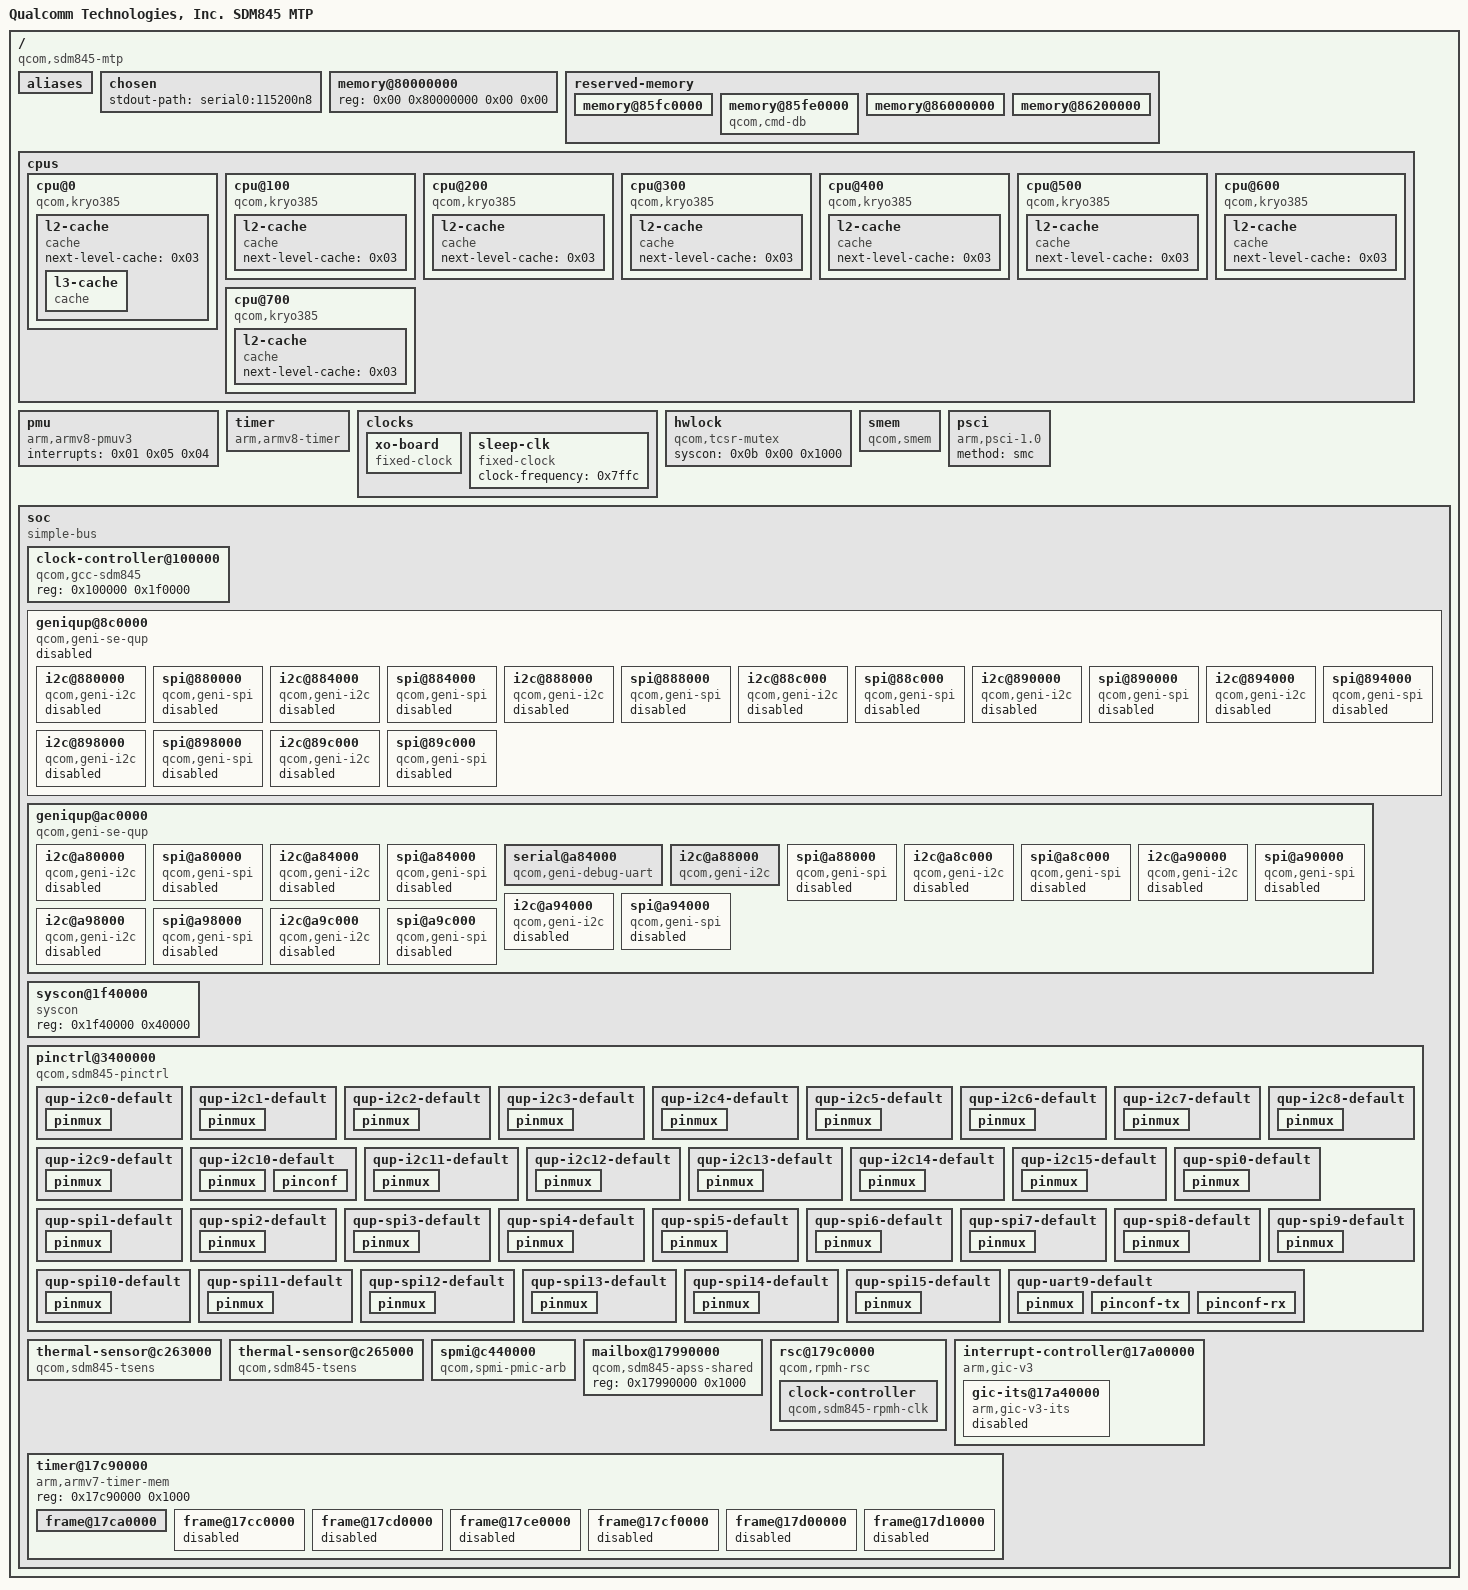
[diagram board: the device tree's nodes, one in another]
/dts-v1/;

/ {
	interrupt-parent = <0x01>;
	#address-cells = <0x02>;
	#size-cells = <0x02>;
	model = "Qualcomm Technologies, Inc. SDM845 MTP";
	compatible = "qcom,sdm845-mtp";

	aliases {
		i2c0 = "/soc/geniqup@8c0000/i2c@880000";
		i2c1 = "/soc/geniqup@8c0000/i2c@884000";
		i2c2 = "/soc/geniqup@8c0000/i2c@888000";
		i2c3 = "/soc/geniqup@8c0000/i2c@88c000";
		i2c4 = "/soc/geniqup@8c0000/i2c@890000";
		i2c5 = "/soc/geniqup@8c0000/i2c@894000";
		i2c6 = "/soc/geniqup@8c0000/i2c@898000";
		i2c7 = "/soc/geniqup@8c0000/i2c@89c000";
		i2c8 = "/soc/geniqup@ac0000/i2c@a80000";
		i2c9 = "/soc/geniqup@ac0000/i2c@a84000";
		i2c10 = "/soc/geniqup@ac0000/i2c@a88000";
		i2c11 = "/soc/geniqup@ac0000/i2c@a8c000";
		i2c12 = "/soc/geniqup@ac0000/i2c@a90000";
		i2c13 = "/soc/geniqup@ac0000/i2c@a94000";
		i2c14 = "/soc/geniqup@ac0000/i2c@a98000";
		i2c15 = "/soc/geniqup@ac0000/i2c@a9c000";
		spi0 = "/soc/geniqup@8c0000/spi@880000";
		spi1 = "/soc/geniqup@8c0000/spi@884000";
		spi2 = "/soc/geniqup@8c0000/spi@888000";
		spi3 = "/soc/geniqup@8c0000/spi@88c000";
		spi4 = "/soc/geniqup@8c0000/spi@890000";
		spi5 = "/soc/geniqup@8c0000/spi@894000";
		spi6 = "/soc/geniqup@8c0000/spi@898000";
		spi7 = "/soc/geniqup@8c0000/spi@89c000";
		spi8 = "/soc/geniqup@ac0000/spi@a80000";
		spi9 = "/soc/geniqup@ac0000/spi@a84000";
		spi10 = "/soc/geniqup@ac0000/spi@a88000";
		spi11 = "/soc/geniqup@ac0000/spi@a8c000";
		spi12 = "/soc/geniqup@ac0000/spi@a90000";
		spi13 = "/soc/geniqup@ac0000/spi@a94000";
		spi14 = "/soc/geniqup@ac0000/spi@a98000";
		spi15 = "/soc/geniqup@ac0000/spi@a9c000";
		serial0 = "/soc/geniqup@ac0000/serial@a84000";
	};

	chosen {
		stdout-path = "serial0:115200n8";
	};

	memory@80000000 {
		device_type = "memory";
		reg = <0x00 0x80000000 0x00 0x00>;
	};

	reserved-memory {
		#address-cells = <0x02>;
		#size-cells = <0x02>;
		ranges;

		memory@85fc0000 {
			reg = <0x00 0x85fc0000 0x00 0x20000>;
			no-map;
		};

		memory@85fe0000 {
			compatible = "qcom,cmd-db";
			reg = <0x00 0x85fe0000 0x00 0x20000>;
			no-map;
		};

		memory@86000000 {
			reg = <0x00 0x86000000 0x00 0x200000>;
			no-map;
			phandle = <0x0c>;
		};

		memory@86200000 {
			reg = <0x00 0x86200000 0x00 0x2d00000>;
			no-map;
		};
	};

	cpus {
		#address-cells = <0x02>;
		#size-cells = <0x00>;

		cpu@0 {
			device_type = "cpu";
			compatible = "qcom,kryo385";
			reg = <0x00 0x00>;
			enable-method = "psci";
			next-level-cache = <0x02>;

			l2-cache {
				compatible = "cache";
				next-level-cache = <0x03>;
				phandle = <0x02>;

				l3-cache {
					compatible = "cache";
					phandle = <0x03>;
				};
			};
		};

		cpu@100 {
			device_type = "cpu";
			compatible = "qcom,kryo385";
			reg = <0x00 0x100>;
			enable-method = "psci";
			next-level-cache = <0x04>;

			l2-cache {
				compatible = "cache";
				next-level-cache = <0x03>;
				phandle = <0x04>;
			};
		};

		cpu@200 {
			device_type = "cpu";
			compatible = "qcom,kryo385";
			reg = <0x00 0x200>;
			enable-method = "psci";
			next-level-cache = <0x05>;

			l2-cache {
				compatible = "cache";
				next-level-cache = <0x03>;
				phandle = <0x05>;
			};
		};

		cpu@300 {
			device_type = "cpu";
			compatible = "qcom,kryo385";
			reg = <0x00 0x300>;
			enable-method = "psci";
			next-level-cache = <0x06>;

			l2-cache {
				compatible = "cache";
				next-level-cache = <0x03>;
				phandle = <0x06>;
			};
		};

		cpu@400 {
			device_type = "cpu";
			compatible = "qcom,kryo385";
			reg = <0x00 0x400>;
			enable-method = "psci";
			next-level-cache = <0x07>;

			l2-cache {
				compatible = "cache";
				next-level-cache = <0x03>;
				phandle = <0x07>;
			};
		};

		cpu@500 {
			device_type = "cpu";
			compatible = "qcom,kryo385";
			reg = <0x00 0x500>;
			enable-method = "psci";
			next-level-cache = <0x08>;

			l2-cache {
				compatible = "cache";
				next-level-cache = <0x03>;
				phandle = <0x08>;
			};
		};

		cpu@600 {
			device_type = "cpu";
			compatible = "qcom,kryo385";
			reg = <0x00 0x600>;
			enable-method = "psci";
			next-level-cache = <0x09>;

			l2-cache {
				compatible = "cache";
				next-level-cache = <0x03>;
				phandle = <0x09>;
			};
		};

		cpu@700 {
			device_type = "cpu";
			compatible = "qcom,kryo385";
			reg = <0x00 0x700>;
			enable-method = "psci";
			next-level-cache = <0x0a>;

			l2-cache {
				compatible = "cache";
				next-level-cache = <0x03>;
				phandle = <0x0a>;
			};
		};
	};

	pmu {
		compatible = "arm,armv8-pmuv3";
		interrupts = <0x01 0x05 0x04>;
	};

	timer {
		compatible = "arm,armv8-timer";
		interrupts = <0x01 0x01 0x08 0x01 0x02 0x08 0x01 0x03 0x08 0x01 0x00 0x08>;
	};

	clocks {

		xo-board {
			compatible = "fixed-clock";
			#clock-cells = <0x00>;
			clock-frequency = <0x249f000>;
			clock-output-names = "xo_board";
		};

		sleep-clk {
			compatible = "fixed-clock";
			#clock-cells = <0x00>;
			clock-frequency = <0x7ffc>;
		};
	};

	hwlock {
		compatible = "qcom,tcsr-mutex";
		syscon = <0x0b 0x00 0x1000>;
		#hwlock-cells = <0x01>;
		phandle = <0x0d>;
	};

	smem {
		compatible = "qcom,smem";
		memory-region = <0x0c>;
		hwlocks = <0x0d 0x03>;
	};

	psci {
		compatible = "arm,psci-1.0";
		method = "smc";
	};

	soc {
		#address-cells = <0x01>;
		#size-cells = <0x01>;
		ranges = <0x00 0x00 0x00 0xffffffff>;
		compatible = "simple-bus";

		clock-controller@100000 {
			compatible = "qcom,gcc-sdm845";
			reg = <0x100000 0x1f0000>;
			#clock-cells = <0x01>;
			#reset-cells = <0x01>;
			#power-domain-cells = <0x01>;
			phandle = <0x0e>;
		};

		geniqup@8c0000 {
			compatible = "qcom,geni-se-qup";
			reg = <0x8c0000 0x6000>;
			clock-names = "m-ahb\0s-ahb";
			clocks = <0x0e 0x64 0x0e 0x65>;
			#address-cells = <0x01>;
			#size-cells = <0x01>;
			ranges;
			status = "disabled";

			i2c@880000 {
				compatible = "qcom,geni-i2c";
				reg = <0x880000 0x4000>;
				clock-names = "se";
				clocks = <0x0e 0x44>;
				pinctrl-names = "default";
				pinctrl-0 = <0x0f>;
				interrupts = <0x00 0x259 0x04>;
				#address-cells = <0x01>;
				#size-cells = <0x00>;
				status = "disabled";
			};

			spi@880000 {
				compatible = "qcom,geni-spi";
				reg = <0x880000 0x4000>;
				clock-names = "se";
				clocks = <0x0e 0x44>;
				pinctrl-names = "default";
				pinctrl-0 = <0x10>;
				interrupts = <0x00 0x259 0x04>;
				#address-cells = <0x01>;
				#size-cells = <0x00>;
				status = "disabled";
			};

			i2c@884000 {
				compatible = "qcom,geni-i2c";
				reg = <0x884000 0x4000>;
				clock-names = "se";
				clocks = <0x0e 0x46>;
				pinctrl-names = "default";
				pinctrl-0 = <0x11>;
				interrupts = <0x00 0x25a 0x04>;
				#address-cells = <0x01>;
				#size-cells = <0x00>;
				status = "disabled";
			};

			spi@884000 {
				compatible = "qcom,geni-spi";
				reg = <0x884000 0x4000>;
				clock-names = "se";
				clocks = <0x0e 0x46>;
				pinctrl-names = "default";
				pinctrl-0 = <0x12>;
				interrupts = <0x00 0x25a 0x04>;
				#address-cells = <0x01>;
				#size-cells = <0x00>;
				status = "disabled";
			};

			i2c@888000 {
				compatible = "qcom,geni-i2c";
				reg = <0x888000 0x4000>;
				clock-names = "se";
				clocks = <0x0e 0x48>;
				pinctrl-names = "default";
				pinctrl-0 = <0x13>;
				interrupts = <0x00 0x25b 0x04>;
				#address-cells = <0x01>;
				#size-cells = <0x00>;
				status = "disabled";
			};

			spi@888000 {
				compatible = "qcom,geni-spi";
				reg = <0x888000 0x4000>;
				clock-names = "se";
				clocks = <0x0e 0x48>;
				pinctrl-names = "default";
				pinctrl-0 = <0x14>;
				interrupts = <0x00 0x25b 0x04>;
				#address-cells = <0x01>;
				#size-cells = <0x00>;
				status = "disabled";
			};

			i2c@88c000 {
				compatible = "qcom,geni-i2c";
				reg = <0x88c000 0x4000>;
				clock-names = "se";
				clocks = <0x0e 0x4a>;
				pinctrl-names = "default";
				pinctrl-0 = <0x15>;
				interrupts = <0x00 0x25c 0x04>;
				#address-cells = <0x01>;
				#size-cells = <0x00>;
				status = "disabled";
			};

			spi@88c000 {
				compatible = "qcom,geni-spi";
				reg = <0x88c000 0x4000>;
				clock-names = "se";
				clocks = <0x0e 0x4a>;
				pinctrl-names = "default";
				pinctrl-0 = <0x16>;
				interrupts = <0x00 0x25c 0x04>;
				#address-cells = <0x01>;
				#size-cells = <0x00>;
				status = "disabled";
			};

			i2c@890000 {
				compatible = "qcom,geni-i2c";
				reg = <0x890000 0x4000>;
				clock-names = "se";
				clocks = <0x0e 0x4c>;
				pinctrl-names = "default";
				pinctrl-0 = <0x17>;
				interrupts = <0x00 0x25d 0x04>;
				#address-cells = <0x01>;
				#size-cells = <0x00>;
				status = "disabled";
			};

			spi@890000 {
				compatible = "qcom,geni-spi";
				reg = <0x890000 0x4000>;
				clock-names = "se";
				clocks = <0x0e 0x4c>;
				pinctrl-names = "default";
				pinctrl-0 = <0x18>;
				interrupts = <0x00 0x25d 0x04>;
				#address-cells = <0x01>;
				#size-cells = <0x00>;
				status = "disabled";
			};

			i2c@894000 {
				compatible = "qcom,geni-i2c";
				reg = <0x894000 0x4000>;
				clock-names = "se";
				clocks = <0x0e 0x4e>;
				pinctrl-names = "default";
				pinctrl-0 = <0x19>;
				interrupts = <0x00 0x25e 0x04>;
				#address-cells = <0x01>;
				#size-cells = <0x00>;
				status = "disabled";
			};

			spi@894000 {
				compatible = "qcom,geni-spi";
				reg = <0x894000 0x4000>;
				clock-names = "se";
				clocks = <0x0e 0x4e>;
				pinctrl-names = "default";
				pinctrl-0 = <0x1a>;
				interrupts = <0x00 0x25e 0x04>;
				#address-cells = <0x01>;
				#size-cells = <0x00>;
				status = "disabled";
			};

			i2c@898000 {
				compatible = "qcom,geni-i2c";
				reg = <0x898000 0x4000>;
				clock-names = "se";
				clocks = <0x0e 0x50>;
				pinctrl-names = "default";
				pinctrl-0 = <0x1b>;
				interrupts = <0x00 0x25f 0x04>;
				#address-cells = <0x01>;
				#size-cells = <0x00>;
				status = "disabled";
			};

			spi@898000 {
				compatible = "qcom,geni-spi";
				reg = <0x898000 0x4000>;
				clock-names = "se";
				clocks = <0x0e 0x50>;
				pinctrl-names = "default";
				pinctrl-0 = <0x1c>;
				interrupts = <0x00 0x25f 0x04>;
				#address-cells = <0x01>;
				#size-cells = <0x00>;
				status = "disabled";
			};

			i2c@89c000 {
				compatible = "qcom,geni-i2c";
				reg = <0x89c000 0x4000>;
				clock-names = "se";
				clocks = <0x0e 0x52>;
				pinctrl-names = "default";
				pinctrl-0 = <0x1d>;
				interrupts = <0x00 0x260 0x04>;
				#address-cells = <0x01>;
				#size-cells = <0x00>;
				status = "disabled";
			};

			spi@89c000 {
				compatible = "qcom,geni-spi";
				reg = <0x89c000 0x4000>;
				clock-names = "se";
				clocks = <0x0e 0x52>;
				pinctrl-names = "default";
				pinctrl-0 = <0x1e>;
				interrupts = <0x00 0x260 0x04>;
				#address-cells = <0x01>;
				#size-cells = <0x00>;
				status = "disabled";
			};
		};

		geniqup@ac0000 {
			compatible = "qcom,geni-se-qup";
			reg = <0xac0000 0x6000>;
			clock-names = "m-ahb\0s-ahb";
			clocks = <0x0e 0x66 0x0e 0x67>;
			#address-cells = <0x01>;
			#size-cells = <0x01>;
			ranges;
			status = "okay";

			i2c@a80000 {
				compatible = "qcom,geni-i2c";
				reg = <0xa80000 0x4000>;
				clock-names = "se";
				clocks = <0x0e 0x54>;
				pinctrl-names = "default";
				pinctrl-0 = <0x1f>;
				interrupts = <0x00 0x161 0x04>;
				#address-cells = <0x01>;
				#size-cells = <0x00>;
				status = "disabled";
			};

			spi@a80000 {
				compatible = "qcom,geni-spi";
				reg = <0xa80000 0x4000>;
				clock-names = "se";
				clocks = <0x0e 0x54>;
				pinctrl-names = "default";
				pinctrl-0 = <0x20>;
				interrupts = <0x00 0x161 0x04>;
				#address-cells = <0x01>;
				#size-cells = <0x00>;
				status = "disabled";
			};

			i2c@a84000 {
				compatible = "qcom,geni-i2c";
				reg = <0xa84000 0x4000>;
				clock-names = "se";
				clocks = <0x0e 0x56>;
				pinctrl-names = "default";
				pinctrl-0 = <0x21>;
				interrupts = <0x00 0x162 0x04>;
				#address-cells = <0x01>;
				#size-cells = <0x00>;
				status = "disabled";
			};

			spi@a84000 {
				compatible = "qcom,geni-spi";
				reg = <0xa84000 0x4000>;
				clock-names = "se";
				clocks = <0x0e 0x56>;
				pinctrl-names = "default";
				pinctrl-0 = <0x22>;
				interrupts = <0x00 0x162 0x04>;
				#address-cells = <0x01>;
				#size-cells = <0x00>;
				status = "disabled";
			};

			serial@a84000 {
				compatible = "qcom,geni-debug-uart";
				reg = <0xa84000 0x4000>;
				clock-names = "se";
				clocks = <0x0e 0x56>;
				pinctrl-names = "default";
				pinctrl-0 = <0x23>;
				interrupts = <0x00 0x162 0x04>;
				status = "okay";
			};

			i2c@a88000 {
				compatible = "qcom,geni-i2c";
				reg = <0xa88000 0x4000>;
				clock-names = "se";
				clocks = <0x0e 0x58>;
				pinctrl-names = "default";
				pinctrl-0 = <0x24>;
				interrupts = <0x00 0x163 0x04>;
				#address-cells = <0x01>;
				#size-cells = <0x00>;
				status = "okay";
				clock-frequency = <0x61a80>;
			};

			spi@a88000 {
				compatible = "qcom,geni-spi";
				reg = <0xa88000 0x4000>;
				clock-names = "se";
				clocks = <0x0e 0x58>;
				pinctrl-names = "default";
				pinctrl-0 = <0x25>;
				interrupts = <0x00 0x163 0x04>;
				#address-cells = <0x01>;
				#size-cells = <0x00>;
				status = "disabled";
			};

			i2c@a8c000 {
				compatible = "qcom,geni-i2c";
				reg = <0xa8c000 0x4000>;
				clock-names = "se";
				clocks = <0x0e 0x5a>;
				pinctrl-names = "default";
				pinctrl-0 = <0x26>;
				interrupts = <0x00 0x164 0x04>;
				#address-cells = <0x01>;
				#size-cells = <0x00>;
				status = "disabled";
			};

			spi@a8c000 {
				compatible = "qcom,geni-spi";
				reg = <0xa8c000 0x4000>;
				clock-names = "se";
				clocks = <0x0e 0x5a>;
				pinctrl-names = "default";
				pinctrl-0 = <0x27>;
				interrupts = <0x00 0x164 0x04>;
				#address-cells = <0x01>;
				#size-cells = <0x00>;
				status = "disabled";
			};

			i2c@a90000 {
				compatible = "qcom,geni-i2c";
				reg = <0xa90000 0x4000>;
				clock-names = "se";
				clocks = <0x0e 0x5c>;
				pinctrl-names = "default";
				pinctrl-0 = <0x28>;
				interrupts = <0x00 0x165 0x04>;
				#address-cells = <0x01>;
				#size-cells = <0x00>;
				status = "disabled";
			};

			spi@a90000 {
				compatible = "qcom,geni-spi";
				reg = <0xa90000 0x4000>;
				clock-names = "se";
				clocks = <0x0e 0x5c>;
				pinctrl-names = "default";
				pinctrl-0 = <0x29>;
				interrupts = <0x00 0x165 0x04>;
				#address-cells = <0x01>;
				#size-cells = <0x00>;
				status = "disabled";
			};

			i2c@a94000 {
				compatible = "qcom,geni-i2c";
				reg = <0xa94000 0x4000>;
				clock-names = "se";
				clocks = <0x0e 0x5e>;
				pinctrl-names = "default";
				pinctrl-0 = <0x2a>;
				interrupts = <0x00 0x166 0x04>;
				#address-cells = <0x01>;
				#size-cells = <0x00>;
				status = "disabled";
			};

			spi@a94000 {
				compatible = "qcom,geni-spi";
				reg = <0xa94000 0x4000>;
				clock-names = "se";
				clocks = <0x0e 0x5e>;
				pinctrl-names = "default";
				pinctrl-0 = <0x2b>;
				interrupts = <0x00 0x166 0x04>;
				#address-cells = <0x01>;
				#size-cells = <0x00>;
				status = "disabled";
			};

			i2c@a98000 {
				compatible = "qcom,geni-i2c";
				reg = <0xa98000 0x4000>;
				clock-names = "se";
				clocks = <0x0e 0x60>;
				pinctrl-names = "default";
				pinctrl-0 = <0x2c>;
				interrupts = <0x00 0x167 0x04>;
				#address-cells = <0x01>;
				#size-cells = <0x00>;
				status = "disabled";
			};

			spi@a98000 {
				compatible = "qcom,geni-spi";
				reg = <0xa98000 0x4000>;
				clock-names = "se";
				clocks = <0x0e 0x60>;
				pinctrl-names = "default";
				pinctrl-0 = <0x2d>;
				interrupts = <0x00 0x167 0x04>;
				#address-cells = <0x01>;
				#size-cells = <0x00>;
				status = "disabled";
			};

			i2c@a9c000 {
				compatible = "qcom,geni-i2c";
				reg = <0xa9c000 0x4000>;
				clock-names = "se";
				clocks = <0x0e 0x62>;
				pinctrl-names = "default";
				pinctrl-0 = <0x2e>;
				interrupts = <0x00 0x168 0x04>;
				#address-cells = <0x01>;
				#size-cells = <0x00>;
				status = "disabled";
			};

			spi@a9c000 {
				compatible = "qcom,geni-spi";
				reg = <0xa9c000 0x4000>;
				clock-names = "se";
				clocks = <0x0e 0x62>;
				pinctrl-names = "default";
				pinctrl-0 = <0x2f>;
				interrupts = <0x00 0x168 0x04>;
				#address-cells = <0x01>;
				#size-cells = <0x00>;
				status = "disabled";
			};
		};

		syscon@1f40000 {
			compatible = "syscon";
			reg = <0x1f40000 0x40000>;
			phandle = <0x0b>;
		};

		pinctrl@3400000 {
			compatible = "qcom,sdm845-pinctrl";
			reg = <0x3400000 0xc00000>;
			interrupts = <0x00 0xd0 0x04>;
			gpio-controller;
			#gpio-cells = <0x02>;
			interrupt-controller;
			#interrupt-cells = <0x02>;
			gpio-reserved-ranges = <0x00 0x04 0x51 0x04>;

			qup-i2c0-default {
				phandle = <0x0f>;

				pinmux {
					pins = "gpio0\0gpio1";
					function = "qup0";
				};
			};

			qup-i2c1-default {
				phandle = <0x11>;

				pinmux {
					pins = "gpio17\0gpio18";
					function = "qup1";
				};
			};

			qup-i2c2-default {
				phandle = <0x13>;

				pinmux {
					pins = "gpio27\0gpio28";
					function = "qup2";
				};
			};

			qup-i2c3-default {
				phandle = <0x15>;

				pinmux {
					pins = "gpio41\0gpio42";
					function = "qup3";
				};
			};

			qup-i2c4-default {
				phandle = <0x17>;

				pinmux {
					pins = "gpio89\0gpio90";
					function = "qup4";
				};
			};

			qup-i2c5-default {
				phandle = <0x19>;

				pinmux {
					pins = "gpio85\0gpio86";
					function = "qup5";
				};
			};

			qup-i2c6-default {
				phandle = <0x1b>;

				pinmux {
					pins = "gpio45\0gpio46";
					function = "qup6";
				};
			};

			qup-i2c7-default {
				phandle = <0x1d>;

				pinmux {
					pins = "gpio93\0gpio94";
					function = "qup7";
				};
			};

			qup-i2c8-default {
				phandle = <0x1f>;

				pinmux {
					pins = "gpio65\0gpio66";
					function = "qup8";
				};
			};

			qup-i2c9-default {
				phandle = <0x21>;

				pinmux {
					pins = "gpio6\0gpio7";
					function = "qup9";
				};
			};

			qup-i2c10-default {
				phandle = <0x24>;

				pinmux {
					pins = "gpio55\0gpio56";
					function = "qup10";
				};

				pinconf {
					pins = "gpio55\0gpio56";
					drive-strength = <0x02>;
					bias-disable;
				};
			};

			qup-i2c11-default {
				phandle = <0x26>;

				pinmux {
					pins = "gpio31\0gpio32";
					function = "qup11";
				};
			};

			qup-i2c12-default {
				phandle = <0x28>;

				pinmux {
					pins = "gpio49\0gpio50";
					function = "qup12";
				};
			};

			qup-i2c13-default {
				phandle = <0x2a>;

				pinmux {
					pins = "gpio105\0gpio106";
					function = "qup13";
				};
			};

			qup-i2c14-default {
				phandle = <0x2c>;

				pinmux {
					pins = "gpio33\0gpio34";
					function = "qup14";
				};
			};

			qup-i2c15-default {
				phandle = <0x2e>;

				pinmux {
					pins = "gpio81\0gpio82";
					function = "qup15";
				};
			};

			qup-spi0-default {
				phandle = <0x10>;

				pinmux {
					pins = "gpio0\0gpio1\0gpio2\0gpio3";
					function = "qup0";
				};
			};

			qup-spi1-default {
				phandle = <0x12>;

				pinmux {
					pins = "gpio17\0gpio18\0gpio19\0gpio20";
					function = "qup1";
				};
			};

			qup-spi2-default {
				phandle = <0x14>;

				pinmux {
					pins = "gpio27\0gpio28\0gpio29\0gpio30";
					function = "qup2";
				};
			};

			qup-spi3-default {
				phandle = <0x16>;

				pinmux {
					pins = "gpio41\0gpio42\0gpio43\0gpio44";
					function = "qup3";
				};
			};

			qup-spi4-default {
				phandle = <0x18>;

				pinmux {
					pins = "gpio89\0gpio90\0gpio91\0gpio92";
					function = "qup4";
				};
			};

			qup-spi5-default {
				phandle = <0x1a>;

				pinmux {
					pins = "gpio85\0gpio86\0gpio87\0gpio88";
					function = "qup5";
				};
			};

			qup-spi6-default {
				phandle = <0x1c>;

				pinmux {
					pins = "gpio45\0gpio46\0gpio47\0gpio48";
					function = "qup6";
				};
			};

			qup-spi7-default {
				phandle = <0x1e>;

				pinmux {
					pins = "gpio93\0gpio94\0gpio95\0gpio96";
					function = "qup7";
				};
			};

			qup-spi8-default {
				phandle = <0x20>;

				pinmux {
					pins = "gpio65\0gpio66\0gpio67\0gpio68";
					function = "qup8";
				};
			};

			qup-spi9-default {
				phandle = <0x22>;

				pinmux {
					pins = "gpio6\0gpio7\0gpio4\0gpio5";
					function = "qup9";
				};
			};

			qup-spi10-default {
				phandle = <0x25>;

				pinmux {
					pins = "gpio55\0gpio56\0gpio53\0gpio54";
					function = "qup10";
				};
			};

			qup-spi11-default {
				phandle = <0x27>;

				pinmux {
					pins = "gpio31\0gpio32\0gpio33\0gpio34";
					function = "qup11";
				};
			};

			qup-spi12-default {
				phandle = <0x29>;

				pinmux {
					pins = "gpio49\0gpio50\0gpio51\0gpio52";
					function = "qup12";
				};
			};

			qup-spi13-default {
				phandle = <0x2b>;

				pinmux {
					pins = "gpio105\0gpio106\0gpio107\0gpio108";
					function = "qup13";
				};
			};

			qup-spi14-default {
				phandle = <0x2d>;

				pinmux {
					pins = "gpio33\0gpio34\0gpio31\0gpio32";
					function = "qup14";
				};
			};

			qup-spi15-default {
				phandle = <0x2f>;

				pinmux {
					pins = "gpio81\0gpio82\0gpio83\0gpio84";
					function = "qup15";
				};
			};

			qup-uart9-default {
				phandle = <0x23>;

				pinmux {
					pins = "gpio4\0gpio5";
					function = "qup9";
				};

				pinconf-tx {
					pins = "gpio4";
					drive-strength = <0x02>;
					bias-disable;
				};

				pinconf-rx {
					pins = "gpio5";
					drive-strength = <0x02>;
					bias-pull-up;
				};
			};
		};

		thermal-sensor@c263000 {
			compatible = "qcom,sdm845-tsens\0qcom,tsens-v2";
			reg = <0xc263000 0x1ff 0xc222000 0x1ff>;
			#qcom,sensors = <0x0d>;
			#thermal-sensor-cells = <0x01>;
		};

		thermal-sensor@c265000 {
			compatible = "qcom,sdm845-tsens\0qcom,tsens-v2";
			reg = <0xc265000 0x1ff 0xc223000 0x1ff>;
			#qcom,sensors = <0x08>;
			#thermal-sensor-cells = <0x01>;
		};

		spmi@c440000 {
			compatible = "qcom,spmi-pmic-arb";
			reg = <0xc440000 0x1100 0xc600000 0x2000000 0xe600000 0x100000 0xe700000 0xa0000 0xc40a000 0x26000>;
			reg-names = "core\0chnls\0obsrvr\0intr\0cnfg";
			interrupt-names = "periph_irq";
			interrupts = <0x00 0x1e1 0x04>;
			qcom,ee = <0x00>;
			qcom,channel = <0x00>;
			#address-cells = <0x02>;
			#size-cells = <0x00>;
			interrupt-controller;
			#interrupt-cells = <0x04>;
			cell-index = <0x00>;
		};

		mailbox@17990000 {
			compatible = "qcom,sdm845-apss-shared";
			reg = <0x17990000 0x1000>;
			#mbox-cells = <0x01>;
		};

		rsc@179c0000 {
			label = "apps_rsc";
			compatible = "qcom,rpmh-rsc";
			reg = <0x179c0000 0x10000 0x179d0000 0x10000 0x179e0000 0x10000>;
			reg-names = "drv-0\0drv-1\0drv-2";
			interrupts = <0x00 0x03 0x04 0x00 0x04 0x04 0x00 0x05 0x04>;
			qcom,tcs-offset = <0xd00>;
			qcom,drv-id = <0x02>;
			qcom,tcs-config = <0x02 0x02 0x00 0x03 0x01 0x03 0x03 0x01>;

			clock-controller {
				compatible = "qcom,sdm845-rpmh-clk";
				#clock-cells = <0x01>;
			};
		};

		interrupt-controller@17a00000 {
			compatible = "arm,gic-v3";
			#address-cells = <0x01>;
			#size-cells = <0x01>;
			ranges;
			#interrupt-cells = <0x03>;
			interrupt-controller;
			reg = <0x17a00000 0x10000 0x17a60000 0x100000>;
			interrupts = <0x01 0x09 0x04>;
			phandle = <0x01>;

			gic-its@17a40000 {
				compatible = "arm,gic-v3-its";
				msi-controller;
				#msi-cells = <0x01>;
				reg = <0x17a40000 0x20000>;
				status = "disabled";
			};
		};

		timer@17c90000 {
			#address-cells = <0x01>;
			#size-cells = <0x01>;
			ranges;
			compatible = "arm,armv7-timer-mem";
			reg = <0x17c90000 0x1000>;

			frame@17ca0000 {
				frame-number = <0x00>;
				interrupts = <0x00 0x07 0x04 0x00 0x06 0x04>;
				reg = <0x17ca0000 0x1000 0x17cb0000 0x1000>;
			};

			frame@17cc0000 {
				frame-number = <0x01>;
				interrupts = <0x00 0x08 0x04>;
				reg = <0x17cc0000 0x1000>;
				status = "disabled";
			};

			frame@17cd0000 {
				frame-number = <0x02>;
				interrupts = <0x00 0x09 0x04>;
				reg = <0x17cd0000 0x1000>;
				status = "disabled";
			};

			frame@17ce0000 {
				frame-number = <0x03>;
				interrupts = <0x00 0x0a 0x04>;
				reg = <0x17ce0000 0x1000>;
				status = "disabled";
			};

			frame@17cf0000 {
				frame-number = <0x04>;
				interrupts = <0x00 0x0b 0x04>;
				reg = <0x17cf0000 0x1000>;
				status = "disabled";
			};

			frame@17d00000 {
				frame-number = <0x05>;
				interrupts = <0x00 0x0c 0x04>;
				reg = <0x17d00000 0x1000>;
				status = "disabled";
			};

			frame@17d10000 {
				frame-number = <0x06>;
				interrupts = <0x00 0x0d 0x04>;
				reg = <0x17d10000 0x1000>;
				status = "disabled";
			};
		};
	};
};
